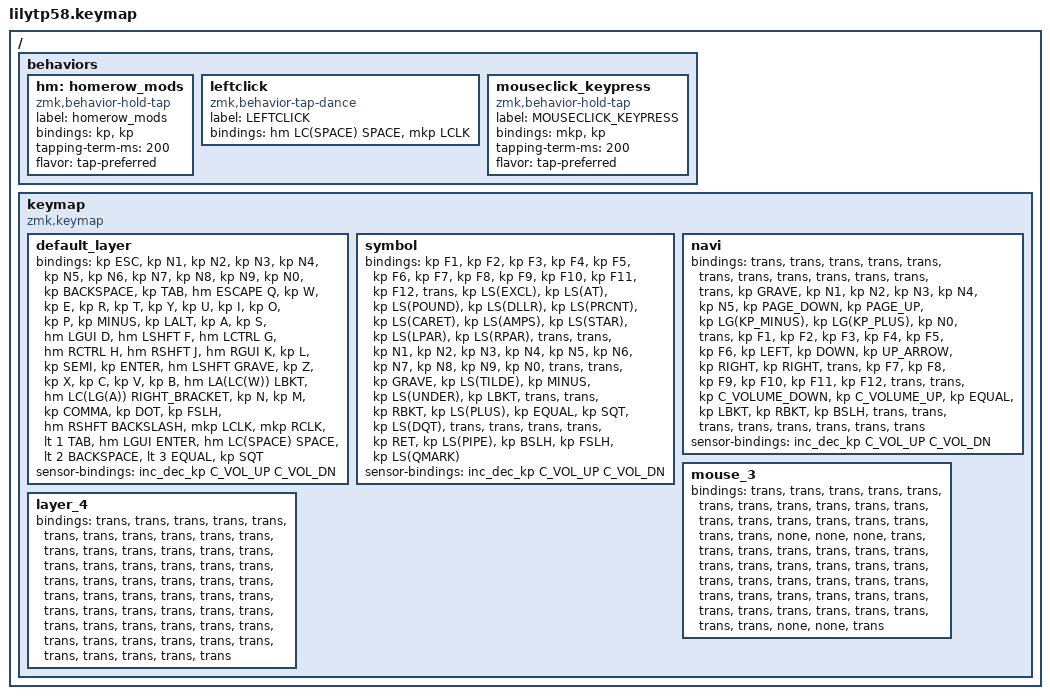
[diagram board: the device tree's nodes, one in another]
/*
 * Copyright (c) 2020 The ZMK Contributors
 *
 * SPDX-License-Identifier: MIT
 */

#define BASE 0
#define LOWER 1
#define MOUSE_KEYS 2
#define MOUSE_TP 3
#define MOUSE_TP_SET 4

/*
 * Defines to enable/disable features
 *
 * These defines allow us to conditionally enable and disable parts of the keymap config.
 *
 * For example, if we decide to build the firmware without the mouse features, we can
 * disable all the config options that rely on those forks and modules without having
 * to edit the entire keymap file manually every time.
 */

#define HAS_MOUSE_KEYS
#define HAS_MOUSE_TP

#include <dt-bindings/zmk/mouse.h>
#include <behaviors/mouse_keys.dtsi>

// We store the trackpoint settings in a separate file
// to make organization a little easier.

#include "include/mouse_tp.dtsi"
#include <behaviors.dtsi>
#include <dt-bindings/zmk/keys.h>

/ {
    behaviors {
        hm: homerow_mods {
            compatible = "zmk,behavior-hold-tap";
            label = "homerow_mods";
            bindings = <&kp>, <&kp>;

            #binding-cells = <2>;
            tapping-term-ms = <200>;
            flavor = "tap-preferred";
        };

        leftclick: leftclick {
            compatible = "zmk,behavior-tap-dance";
            label = "LEFTCLICK";
            #binding-cells = <0>;
            bindings = <&hm LC(SPACE) SPACE>, <&mkp LCLK>;
        };

        mouseclick_keypress: mouseclick_keypress {
            compatible = "zmk,behavior-hold-tap";
            label = "MOUSECLICK_KEYPRESS";
            bindings = <&mkp>, <&kp>;

            #binding-cells = <2>;
            tapping-term-ms = <200>;
            flavor = "tap-preferred";
        };
    };

    keymap {
        compatible = "zmk,keymap";

        default_layer {
            // ------------------------------------------------------------------------------------------------------------
            // |  ESC  |  1  |  2  |  3   |  4   |  5   |                   |  6   |  7    |  8    |  9   |   0   |   `   |
            // |  TAB  |  Q  |  W  |  E   |  R   |  T   |                   |  Y   |  U    |  I    |  O   |   P   |   -   |
            // |  CTRL |  A  |  S  |  D   |  F   |  G   |                   |  H   |  J    |  K    |  L   |   ;   |   '   |
            // | SHIFT |  Z  |  X  |  C   |  V   |  B   |   "["  |  |  "]"  |  N   |  M    |  ,    |  .   |   /   | SHIFT |
            //                     | ALT  | GUI  | LOWER|  SPACE |  | ENTER | RAISE| BSPC  | GUI   |

            bindings = <
&kp ESC  &kp N1  &kp N2  &kp N3  &kp N4  &kp N5  &kp N6  &kp N7  &kp N8  &kp N9  &kp N0  &kp BACKSPACE  &kp TAB  &hm ESCAPE Q  &kp W  &kp E  &kp R  &kp T  &kp Y  &kp U  &kp I  &kp O  &kp P  &kp MINUS  &kp LALT  &kp A  &kp S  &hm LGUI D  &hm LSHFT F  &hm LCTRL G  &hm RCTRL H  &hm RSHFT J  &hm RGUI K  &kp L  &kp SEMI  &kp ENTER  &hm LSHFT GRAVE  &kp Z  &kp X  &kp C  &kp V  &kp B  &hm LA(LC(W)) LBKT  &hm LC(LG(A)) RIGHT_BRACKET  &kp N  &kp M  &kp COMMA  &kp DOT  &kp FSLH  &hm RSHFT BACKSLASH  &mkp LCLK  &mkp RCLK  &lt 1 TAB  &hm LGUI ENTER  &hm LC(SPACE) SPACE  &lt 2 BACKSPACE  &lt 3 EQUAL  &kp SQT
            >;

            sensor-bindings = <&inc_dec_kp C_VOL_UP C_VOL_DN>;
        };

        symbol {
            // ------------------------------------------------------------------------------------------------------------
            // | BTCLR | BT1 | BT2 |  BT3 |  BT4 |  BT5 |                   |      |       |       |      |       |       |
            // |  F1   |  F2 |  F3 |  F4  |  F5  |  F6  |                   |  F7  |  F8   |  F9   |  F10 |  F11  |  F12  |
            // |   `   |  !  |  @  |  #   |  $   |  %   |                   |  ^   |  &    |  *    |  (   |   )   |   ~   |
            // |       |     |     |      |      |      |        |  |       |      |  _    |  +    |  {   |   }   |  "|"  |
            //                     |      |      |      |        |  |       |      |       |       |

            bindings = <
&kp F1  &kp F2  &kp F3  &kp F4  &kp F5  &kp F6  &kp F7  &kp F8  &kp F9  &kp F10  &kp F11  &kp F12  &trans  &kp LS(EXCL)  &kp LS(AT)  &kp LS(POUND)  &kp LS(DLLR)  &kp LS(PRCNT)  &kp LS(CARET)  &kp LS(AMPS)  &kp LS(STAR)  &kp LS(LPAR)  &kp LS(RPAR)  &trans  &trans  &kp N1  &kp N2  &kp N3  &kp N4  &kp N5  &kp N6  &kp N7  &kp N8  &kp N9  &kp N0  &trans  &trans  &kp GRAVE  &kp LS(TILDE)  &kp MINUS  &kp LS(UNDER)  &kp LBKT  &trans  &trans  &kp RBKT  &kp LS(PLUS)  &kp EQUAL  &kp SQT  &kp LS(DQT)  &trans  &trans  &trans  &trans  &kp RET  &kp LS(PIPE)  &kp BSLH  &kp FSLH  &kp LS(QMARK)
            >;

            sensor-bindings = <&inc_dec_kp C_VOL_UP C_VOL_DN>;
        };

        navi {
            // ------------------------------------------------------------------------------------------------------------
            // |       |     |     |      |      |      |                   |      |       |       |      |       |       |
            // |   `   |  1  |  2  |  3   |  4   |  5   |                   |  6   |   7   |   8   |  9   |   0   |       |
            // |   F1  |  F2 |  F3 |  F4  |  F5  |  F6  |                   |      |   <-  |   v   |  ^   |  ->   |       |
            // |   F7  |  F8 |  F9 |  F10 |  F11 |  F12 |        |  |       |  +   |   -   |   =   |  [   |   ]   |   \   |
            //                     |      |      |      |        |  |       |      |       |       |

            bindings = <
&trans  &trans  &trans  &trans  &trans  &trans  &trans  &trans  &trans  &trans  &trans  &trans  &kp GRAVE  &kp N1  &kp N2  &kp N3  &kp N4  &kp N5  &kp PAGE_DOWN  &kp PAGE_UP  &kp LG(KP_MINUS)  &kp LG(KP_PLUS)  &kp N0  &trans  &kp F1  &kp F2  &kp F3  &kp F4  &kp F5  &kp F6  &kp LEFT  &kp DOWN  &kp UP_ARROW  &kp RIGHT  &kp RIGHT  &trans  &kp F7  &kp F8  &kp F9  &kp F10  &kp F11  &kp F12  &trans  &trans  &kp C_VOLUME_DOWN  &kp C_VOLUME_UP  &kp EQUAL  &kp LBKT  &kp RBKT  &kp BSLH  &trans  &trans  &trans  &trans  &trans  &trans  &trans  &trans
            >;

            sensor-bindings = <&inc_dec_kp C_VOL_UP C_VOL_DN>;
        };

        mouse_3 {
            bindings = <
&trans  &trans  &trans  &trans  &trans  &trans  &trans  &trans  &trans  &trans  &trans  &trans  &trans  &trans  &trans  &trans  &trans  &trans  &trans  &none  &none  &none  &trans  &trans  &trans  &trans  &trans  &trans  &trans  &trans  &trans  &trans  &trans  &trans  &trans  &trans  &trans  &trans  &trans  &trans  &trans  &trans  &trans  &trans  &trans  &trans  &trans  &trans  &trans  &trans  &trans  &trans  &trans  &trans  &trans  &none  &none  &trans
            >;
        };

        layer_4 {
            bindings = <
&trans  &trans  &trans  &trans  &trans  &trans  &trans  &trans  &trans  &trans  &trans  &trans  &trans  &trans  &trans  &trans  &trans  &trans  &trans  &trans  &trans  &trans  &trans  &trans  &trans  &trans  &trans  &trans  &trans  &trans  &trans  &trans  &trans  &trans  &trans  &trans  &trans  &trans  &trans  &trans  &trans  &trans  &trans  &trans  &trans  &trans  &trans  &trans  &trans  &trans  &trans  &trans  &trans  &trans  &trans  &trans  &trans  &trans
            >;
        };
    };
};
